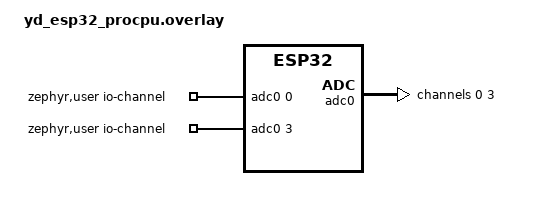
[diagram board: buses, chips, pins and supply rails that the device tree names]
/*
 * Copyright (c) 2022 Wolter HV <wolterhv@gmx.de>
 * Copyright (c) 2023 Benjamin Björnsson <benjamin.bjornsson@gmail.com>
 *
 * SPDX-License-Identifier: Apache-2.0
 */

/ {
	zephyr,user {
		/* adjust channel number according to pinmux in board.dts */
		io-channels = <&adc0 0>, <&adc0 3>;
	};
};

&adc0 {
	#address-cells = <1>;
	#size-cells = <0>;
	status = "okay";

	channel@0 {
		reg = <0>;
		zephyr,gain = "ADC_GAIN_1";
		zephyr,reference = "ADC_REF_INTERNAL";
		zephyr,acquisition-time = <ADC_ACQ_TIME_DEFAULT>;
		zephyr,resolution = <12>;
	};

	channel@3 {
		reg = <3>;
		zephyr,gain = "ADC_GAIN_1";
		zephyr,reference = "ADC_REF_INTERNAL";
		zephyr,acquisition-time = <ADC_ACQ_TIME_DEFAULT>;
		zephyr,resolution = <12>;
	};
};
